# AT32UC3L0256 device description
Architecture: AVR32_UC3; Family: AVR UC3
Registers are 32-bit, read-write, reset 0x0 unless marked. A register's access mark holds for its fields unless they carry their own. Offsets are from the block's base; [hi:lo] are bit positions; {n}, {i} and the like mark numbered series; 'fields as' and 'values as' point back to an identical list.

## OCD — On Chip Debug System
Instances: OCD 0 in dbgreg
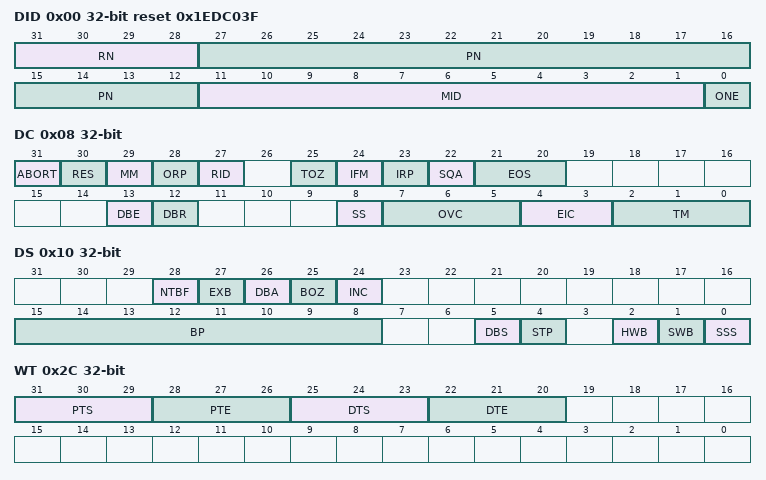
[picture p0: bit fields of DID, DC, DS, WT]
0x00 DID ro reset 0x1EDC03F — Device ID
  [31:28] RN — Revision Number
  [27:12] PN — Product Number
  [11:1] MID — Manufacturer ID
  [0] ONE — Always reads as 1
0x08 DC — Development Control
  [31] ABORT
  [30] RES — Application Reset
  [29] MM — Monitor Mode
  [28] ORP — OCD Register Protect
  [27] RID — Run In Debug
  [25] TOZ — Trap Opcode Zero
  [24] IFM — Ignore First Match
  [23] IRP — Instruction Replace
  [22] SQA — Software Quality Assurance
  [21:20] EOS — Event Out Select
    0=NOP; 1=DEBUG_MODE; 2=BREAKPOINT_WATCHPOINT; 3=THQ
  [13] DBE — Debug Enable
  [12] DBR — Debug Request
  [8] SS — Single Step
  [7:5] OVC — Overrun Control
    0=OVERRUN; 1=DELAY_CPU_BTM; 2=DELAY_CPU_DTM; 3=DELAY_CPU_BTM_DTM
  [4:3] EIC — EVTI Control
    0=PROGRAM_AND_DATA_TRACE; 1=BREAKPOINT; 2=NOP
  [2:0] TM — Trace Mode
0x10 DS ro — Development Status
  [28] NTBF — NanoTrace Buffer Full
  [27] EXB — External Breakpoint
  [26] DBA — Debug Acknowledge
  [25] BOZ — Break on Opcode Zero
  [24] INC — Instruction Complete
  [15:8] BP — Breakpoint Status
  [5] DBS — Debug Status
  [4] STP — Stop Status
  [2] HWB — Hardware Breakpoint Status
  [1] SWB — Software Breakpoint Status
  [0] SSS — Single Step Status
0x2C WT
  [31:29] PTS — Program Trace Start
    0=DISABLED; 1=PROGRAM_0B; 2=PROGRAM_1A; 3=PROGRAM_1B; 4=PROGRAM_2A; 5=PROGRAM_2B; 6=DATA_3A; 7=DATA_3B
  [28:26] PTE — Program Trace End
  [25:23] DTS — Data Trace Start
  [22:20] DTE — Data Trace End
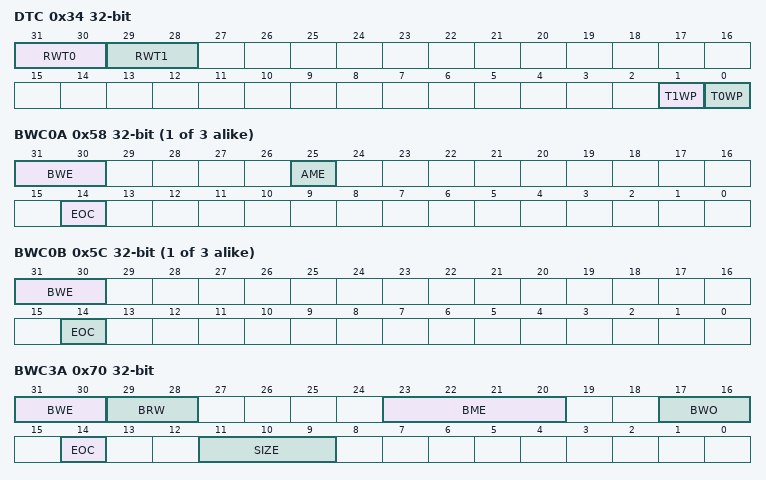
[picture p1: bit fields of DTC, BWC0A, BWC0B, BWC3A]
0x34 DTC — Data Trace Control
  [31:30] RWT0 — Read/Write Trace Channel 0
    0=NO_TRACE; 1=DATA_READ; 2=DATA_WRITE; 3=DATA_READ_WRITE
  [29:28] RWT1 — Read/Write Trace Channel 1
    0=NO_TRACE; 1=DATA_READ; 2=DATA_WRITE; 3=DATA_READ_WRITE
  [1] T1WP — Trace Channel 1 Watchpoint
  [0] T0WP — Trace Channel 0 Watchpoint
0x38 DTSA0 — Data Trace Start Address Channel 0
  [31:0] DTSA — Start adress for trace visibility
0x3C DTSA1 — Data Trace Start Address Channel 1
  [31:0] DTSA — Start adress for trace visibility
0x48 DTEA0 — Data Trace End Address Channel 0
  [31:0] DTEA — End adress for trace visibility
0x4C DTEA1 — Data Trace End Address Channel 1
  [31:0] DTEA — End adress for trace visibility
{0x58+8i} BWC{i}A (i=0..2) — PC Breakpoint/Watchpoint Control {i}A
  [31:30] BWE — Breakpoint/Watchpoint Enable
    0=DISABLED; 1=BREAKPOINT_ENABLED; 3=WATCHPOINT_ENABLED
  [25] AME — Address Mask Enable
  [14] EOC — EVTO Control
{0x5C+8i} BWC{i}B (i=0..2) — PC Breakpoint/Watchpoint Control {i}B
  [31:30] BWE — Breakpoint/Watchpoint Enable
    0=DISABLED; 1=BREAKPOINT_ENABLED; 3=WATCHPOINT_ENABLED
  [14] EOC — EVTO Control
0x70 BWC3A — Data Breakpoint/Watchpoint Control 3A
  [31:30] BWE — Breakpoint/Watchpoint Enable
    0=DISABLED; 1=BREAKPOINT_ENABLED; 3=WATCHPOINT_ENABLED
  [29:28] BRW — Breakpoint/Watchpoint Read/Write Select
    0=READ_BREAK; 1=WRITE_BREAK; 2=ANY_ACCES_BREAK
  [23:20] BME — Breakpoint/Watchpoint Data Mask
  [17:16] BWO — Breakpoint/Watchpoint Operand
  [14] EOC — EVTO Control
  [11:9] SIZE — Size bits to match
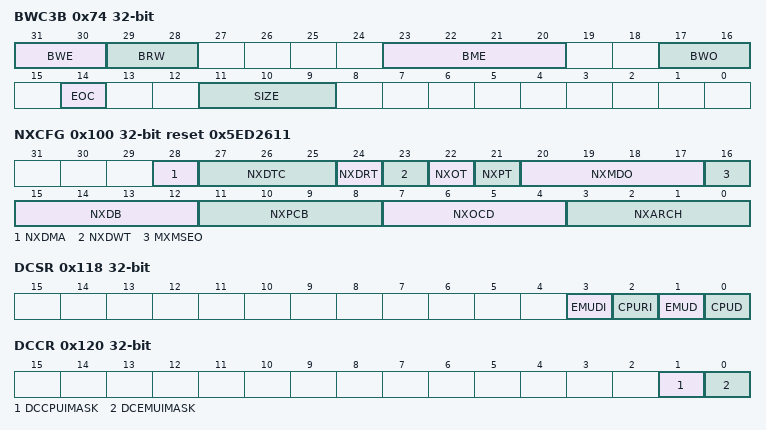
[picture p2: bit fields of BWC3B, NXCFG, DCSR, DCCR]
0x74 BWC3B — Data Breakpoint/Watchpoint Control 3B
  fields as BWC3A
{0x78+8i} BWA{i}A (i=0..2) — PC Breakpoint/Watchpoint Address {i}A
  [31:0] BWA — Breakpoint/Watchpoint Address
{0x7C+8i} BWA{i}B (i=0..2) — PC Breakpoint/Watchpoint Address {i}B
  [31:0] BWA — Breakpoint/Watchpoint Address
0x90 BWA3A — Data Breakpoint/Watchpoint Address 3A
  [31:0] BWA — Address of data for breakpoint or watchpoint generation.
0x94 BWA3B — Data Breakpoint/Watchpoint Address 3B
  fields as BWA3A
0x98 BWD3A — Breakpoint/Watchpoint Data 3A
  [31:0] BWD — Breakpoint/Watchpoint Data
0x9C BWD3B — Breakpoint/Watchpoint Data 3B
  [31:0] BWD — Breakpoint/Watchpoint Data
0x100 NXCFG ro reset 0x5ED2611 — Nexus Configuration
  [28] NXDMA — Direct Memory Access Support
  [27:25] NXDTC — Data Trace Channels
  [24] NXDRT — Data Read Trace Support
  [23] NXDWT — Data Write Trace Support
  [22] NXOT — Ownership Trace Support
  [21] NXPT — Program Trace Support
  [20:17] NXMDO — AUX MDO Pins
  [16] MXMSEO — AUX MSEO Pins
  [15:12] NXDB — Number of Data breakpoints
  [11:8] NXPCB — Number of PC breakpoints
  [7:4] NXOCD — OCD Version
  [3:0] NXARCH — Architecture
0x104 DINST — Debug Instruction
0x108 DPC — Debug Program Counter
0x110 DCCPU — Debug Communication CPU
  [31:0] DATA — Data value
0x114 DCEMU — Debug Communication Emulator
  [31:0] DATA — Data value
0x118 DCSR — Debug Communication Status
  [3] EMUDI — Emulator Data Dirty interrupt flag
  [2] CPURI — CPU Data read Interrupt flag
  [1] EMUD — Emulator Data Dirty
  [0] CPUD — CPU Data Dirty
0x11C PID — Ownership Trace Process ID
  [31:0] PROCESS — Process ID
0x120 DCCR — Debug Communication Control Register.
  [1] DCCPUIMASK — DCCPU Interrupt Mask
  [0] DCEMUIMASK — DCEMU Interrupt Mask
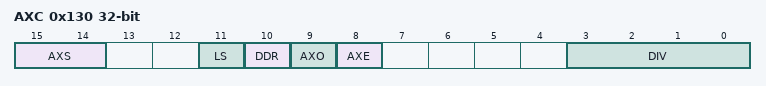
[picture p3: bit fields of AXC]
0x130 AXC — AUX Port Control
  [15:14] AXS — Auxiliary Port Select
  [11] LS — Low Speed
  [10] DDR — Double Data Rate
  [9] AXO — Auxiliary Port Override
  [8] AXE — Auxiliary Port Enable
  [3:0] DIV — Division factor
Value list SIZE: 4=BYTE_ACCESS; 5=HALFWORD_ACCESS; 6=WORD_ACCESS; 7=DOUBLE_WORD_ACCESS
Value list ntbc: 0=OVER; 1=DISABLE; 2=BREAK_STOP; 3=BREAK_FLUSH
Value list op: 0=NONE; 1=CRC; 2=NTRACE; 3=MBIST
Value list state: 0=DONE; 1=BUSY; 2=NOT_IMPL; 3=BUS_ERR; 4=FAILED; 5=LOCKED; 6=CANCELED
